AUTOSAR XML (schema 4.0)
package /ADAS_Components
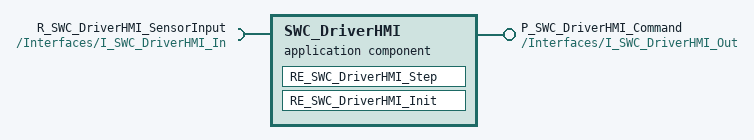
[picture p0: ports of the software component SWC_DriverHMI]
  application sw component type SWC_DriverHMI  # AUTOSAR Application SWC SWC_DriverHMI for ADAS control sub-system
    provide port P_SWC_DriverHMI_Command: provided-interface=/Interfaces/I_SWC_DriverHMI_Out
    require port R_SWC_DriverHMI_SensorInput: required-interface=/Interfaces/I_SWC_DriverHMI_In
    behavior SWC_DriverHMI_Behavior
      runnable RE_SWC_DriverHMI_Step: symbol=SWC_DriverHMI_Step
      runnable RE_SWC_DriverHMI_Init: symbol=SWC_DriverHMI_Init
  sender receiver interface I_SWC_DriverHMI_Out  # Sender Receiver Interface for SWC_DriverHMI outputs
    data DE_SWC_DriverHMI_Signal: type=/AUTOSAR/Platform/uint32
  sender receiver interface I_SWC_DriverHMI_In  # Sender Receiver Interface for SWC_DriverHMI inputs
    data DE_SWC_DriverHMI_RawData: type=/AUTOSAR/Platform/uint16
